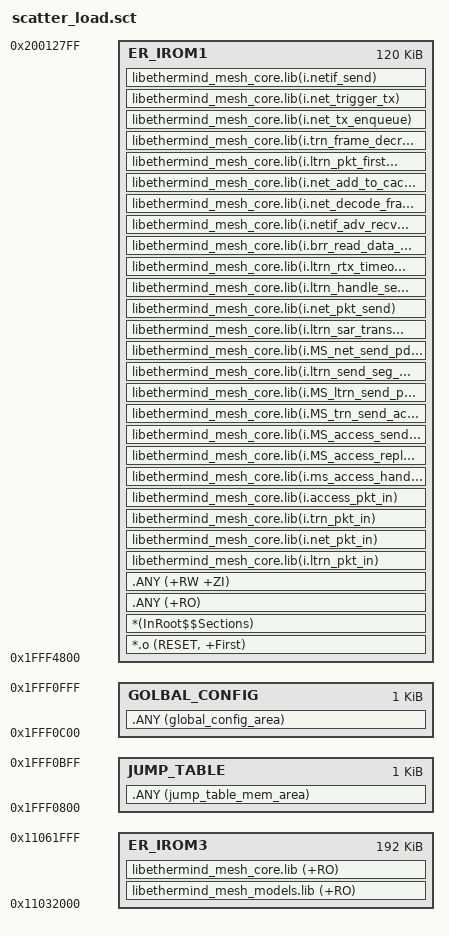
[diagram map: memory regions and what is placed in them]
; *************************************************************
; *** Scatter-Loading Description File generated by uVision ***
; *************************************************************

LR_IROM1 0x1fff4800 0x0001e000{;0x0001e800 {  ; load region size_region
  ER_IROM1 0x1fff4800 0x0001e000  {  ; load address = execution address
   *.o (RESET, +First)
   *(InRoot$$Sections)
   .ANY (+RO)  
   .ANY (+RW +ZI)
   libethermind_mesh_core.lib(i.ltrn_pkt_in)
   libethermind_mesh_core.lib(i.net_pkt_in)
   libethermind_mesh_core.lib(i.trn_pkt_in)
   libethermind_mesh_core.lib(i.access_pkt_in)
   libethermind_mesh_core.lib(i.ms_access_handle_rx_opcode)
   libethermind_mesh_core.lib(i.MS_access_reply)
   libethermind_mesh_core.lib(i.MS_access_send_pdu)
   libethermind_mesh_core.lib(i.MS_trn_send_access_pdu)
   libethermind_mesh_core.lib(i.MS_ltrn_send_pdu)
   libethermind_mesh_core.lib(i.ltrn_send_seg_pdu)
   libethermind_mesh_core.lib(i.MS_net_send_pdu)
   libethermind_mesh_core.lib(i.ltrn_sar_transmit_segment)
   libethermind_mesh_core.lib(i.net_pkt_send)
   libethermind_mesh_core.lib(i.ltrn_handle_segment_ack)
   libethermind_mesh_core.lib(i.ltrn_rtx_timeout_handler)
   libethermind_mesh_core.lib(i.brr_read_data_ind)
   libethermind_mesh_core.lib(i.netif_adv_recv_cb)
   libethermind_mesh_core.lib(i.net_decode_frame)
   libethermind_mesh_core.lib(i.net_add_to_cache)
   libethermind_mesh_core.lib(i.ltrn_pkt_first_process)
   libethermind_mesh_core.lib(i.trn_frame_decrypt_pdu)
   libethermind_mesh_core.lib(i.net_tx_enqueue)
   libethermind_mesh_core.lib(i.net_trigger_tx)
   libethermind_mesh_core.lib(i.netif_send)

  }
 }
  
 
LR_IROM2  0x1fff0800 0x00800 {
  JUMP_TABLE 0x1fff0800 0x00400  {
   .ANY (jump_table_mem_area) 
	
  }
  GOLBAL_CONFIG 0x1fff0c00 0x00400  {
   .ANY (global_config_area) 
	
  }  
 } 

LR_IROM3  0x11032000 0x030000 {
  ER_IROM3 0x11032000 0x030000  {  ; load address = execution address
   libethermind_mesh_models.lib (+RO) 
   ;libethermind_utils.lib (+RO) 
   libethermind_mesh_core.lib (+RO) 
   ;devinfoservice.o(+RO)
   ;gatt*.o(+RO)
   ;gatt_client.o(+RO)
   ;cli_*.o (+RO)
   ;sm*.o (+RO)
   ;appl_*.o (+RO)
  }
 }  


